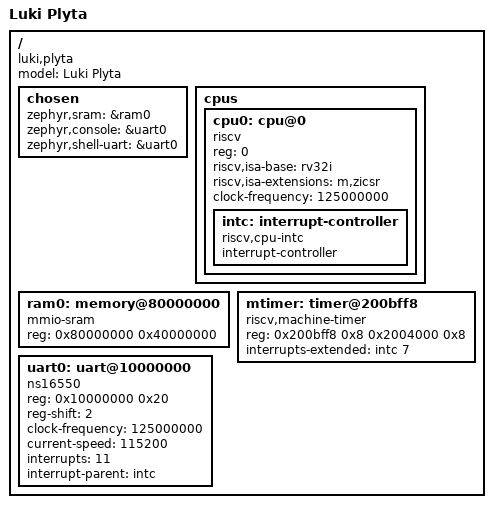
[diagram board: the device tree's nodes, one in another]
/dts-v1/;

/ {
	#address-cells = <1>;
	#size-cells = <1>;
	model = "Luki Plyta";
	compatible = "luki,plyta";

	chosen {
		zephyr,sram      = &ram0;
		zephyr,console   = &uart0;
		zephyr,shell-uart = &uart0;
	};

	cpus {
		#address-cells = <1>;
		#size-cells = <0>;

		cpu0: cpu@0 {
			compatible = "riscv";
			device_type = "cpu";
			reg = <0>;
			riscv,isa-base = "rv32i";
			riscv,isa-extensions = "m,zicsr";
			clock-frequency = <125000000>;

			intc: interrupt-controller {
				compatible = "riscv,cpu-intc";
				#interrupt-cells = <1>;
				interrupt-controller;
			};
		};
	};

	/* 1 GB at 0x80000000 */
	ram0: memory@80000000 {
		device_type = "memory";
		compatible = "mmio-sram";
		reg = <0x80000000 0x40000000>;
	};

	/* SiFive-compatible CLINT */
	/* mtime    @ 0x0200BFF8 — matches your test code exactly */
	/* mtimecmp @ 0x02004000 — matches your test code exactly */
	// clint: clint@2000000 {
	// 	compatible = "sifive,clint0";
	// 	interrupts-extended = <&intc 3   /* MSIP */
	// 	                       &intc 7>; /* MTIP */
	// 	reg = <0x02000000 0x10000>;
	// };

mtimer: timer@200bff8 {
    compatible = "riscv,machine-timer";
    reg = <0x200bff8 0x8
           0x2004000 0x8>;
    reg-names = "mtime", "mtimecmp";
    interrupts-extended = <&intc 7>;
};

	/* ns16550 UART, 4-byte register stride */
	/* divisor 54 → 115200 baud @ 100 MHz  */
	uart0: uart@10000000 {
		compatible = "ns16550";
		reg = <0x10000000 0x20>;
		reg-shift = <2>;
		clock-frequency = <125000000>;
		current-speed = <115200>;
		interrupts = <11>;
		interrupt-parent = <&intc>;
		status = "okay";
		/* no interrupts — no PLIC, polling mode only */
	};
};
